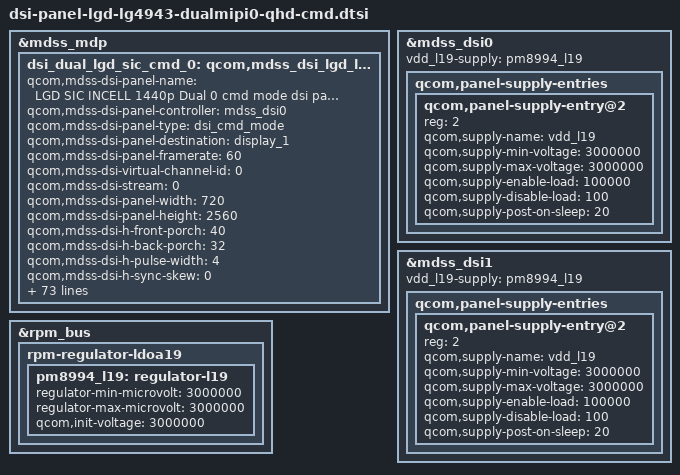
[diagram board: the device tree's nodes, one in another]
/* Copyright (c) 2014, Code Aurora Forum. All rights reserved.
 *
 * This program is free software; you can redistribute it and/or modify
 * it under the terms of the GNU General Public License version 2 and
 * only version 2 as published by the Free Software Foundation.
 *
 * This program is distributed in the hope that it will be useful,
 * but WITHOUT ANY WARRANTY; without even the implied warranty of
 * MERCHANTABILITY or FITNESS FOR A PARTICULAR PURPOSE.  See the
 * GNU General Public License for more details.
 */

&mdss_mdp {
	dsi_dual_lgd_sic_cmd_0: qcom,mdss_dsi_lgd_lg4943_1440p_mipi0_cmd {
		qcom,mdss-dsi-panel-name = "LGD SIC INCELL 1440p Dual 0 cmd mode dsi panel";
		qcom,mdss-dsi-panel-controller = <&mdss_dsi0>;
		qcom,mdss-dsi-panel-type = "dsi_cmd_mode";
		qcom,mdss-dsi-panel-destination = "display_1";
		qcom,mdss-dsi-panel-framerate = <60>;
		qcom,mdss-dsi-virtual-channel-id = <0>;
		qcom,mdss-dsi-stream = <0>;
		qcom,mdss-dsi-panel-width = <720>;
		qcom,mdss-dsi-panel-height = <2560>;
		qcom,mdss-dsi-h-front-porch = <40>;
		qcom,mdss-dsi-h-back-porch = <32>;
		qcom,mdss-dsi-h-pulse-width = <4>;
		qcom,mdss-dsi-h-sync-skew = <0>;
		qcom,mdss-dsi-v-back-porch = <50>;
		qcom,mdss-dsi-v-front-porch = <704>;
		qcom,mdss-dsi-v-pulse-width = <1>;
		qcom,mdss-dsi-h-left-border = <0>;
		qcom,mdss-dsi-h-right-border = <0>;
		qcom,mdss-dsi-v-top-border = <0>;
		qcom,mdss-dsi-v-bottom-border = <0>;
		qcom,mdss-dsi-bpp = <24>;
		qcom,mdss-dsi-color-order = "rgb_swap_rgb";
		qcom,mdss-dsi-underflow-color = <0xff>;
		qcom,mdss-dsi-border-color = <0>;
		qcom,mdss-dsi-h-sync-pulse = <0>;
		qcom,mdss-dsi-traffic-mode = "burst_mode";
		qcom,mdss-dsi-lane-map = "lane_map_0123";
		qcom,mdss-dsi-lane-hs = <1>;
		qcom,mdss-dsi-bllp-eof-power-mode;
		qcom,mdss-dsi-bllp-power-mode;
		qcom,cmd-sync-wait-broadcast;

		qcom,mdss-dsi-lane-0-state;
		qcom,mdss-dsi-lane-1-state;
		qcom,mdss-dsi-lane-2-state;
		qcom,mdss-dsi-lane-3-state;
		qcom,mdss-dsi-hor-line-idle = <0 40 256>,
						<40 120 128>,
						<120 240 64>;
		qcom,mdss-dsi-panel-timings = [F7 3A 28 00 6E 62
						3E 3E 31 03 04 00];//Increase T_HS_prepre 20ns
		qcom,mdss-dsi-reset-sequence = <1 10>, <0 10>, <1 10>;
		qcom,mdss-dsi-t-clk-post = <0x02>;
		lge,mdss-dsi-t-clk-post_for_jdi_ab = <0x32>;
		qcom,mdss-dsi-t-clk-pre = <0x2D>;
		qcom,mdss-dsi-bl-max-level = <4095>;
		qcom,mdss-dsi-dma-trigger = "trigger_sw";
		qcom,mdss-dsi-mdp-trigger = "none";
		qcom,mdss-dsi-te-pin-select = <1>;
		qcom,mdss-dsi-wr-mem-start = <0x2c>;
		qcom,mdss-dsi-wr-mem-continue = <0x3c>;
		qcom,mdss-dsi-te-dcs-command = <1>;
		qcom,mdss-dsi-te-check-enable;
		qcom,mdss-dsi-te-using-te-pin;
		qcom,suspend-ulps-enabled;
		qcom,mdss-dsi-tx-eot-append;
		/* Partial update */
		//qcom,partial-update-enabled;
		qcom,partial-update-roi-merge;
		qcom,panel-roi-alignment = <8 8 4 4 32 32>;
		lge,partial-update-max-left = <1439>;
		lge,partial-update-min-right = <0>;
		qcom,mdss-dsi-on-command = [
			/* Manufacturer Command Protection */
			15 01 00 00 00 00 02 B0 AC
			/* MIPI DPI Configuration */
			39 01 00 00 00 00 06 B1 07 00 80 00 00
			/* Display Control 1 */
			39 01 00 00 00 00 08 B3 0A 14 28 C8 12 94 02
			/* Display Control 2 */
			39 01 00 00 00 00 0B B4 97 B4 0A 0A 0A 0A 14 14 14 14
			/* Display Control 3 */
			39 01 00 00 00 00 0F B5 28 10 20 C8 22 09 09 09 09 D0 50 50 50 50
			/* Display Control 4 */
			39 01 00 00 00 00 05 B6 10 10 A0 00
			/* Display Mode Setting */
			39 01 00 00 00 00 03 B7 4C 00
			/* Panel Setting */
			39 01 00 00 00 00 04 B8 70 91 3F
			/* Internal Oscillator Setting */
			39 01 00 00 00 00 04 C0 10 10 19
			/* Power Control 1 */
			39 01 00 00 00 00 06 C1 01 87 F0 C2 CF
			/* Power Control 2 */
			39 01 00 00 00 00 02 C2 CC
			/* Power Control 3 */
			39 01 00 00 00 00 06 C3 30 74 22 26 21
			/* Power Control 5 */
			39 01 00 00 00 00 07 C5 22 20 A2 52 07 07
			/* Positive Gamma Curve For Red */
			39 01 00 00 00 00 0E D0 8B 10 25 36 44 4C 3F 36 27 19 06 01 03
			/* Negative Gamma Curve For Red */
			39 01 00 00 00 00 0E D1 0B 10 25 36 44 4C 3F 36 27 19 06 01 03
			/* Positive Gamma Curve For Green */
			39 01 00 00 00 00 0E D2 8B 10 25 36 44 4C 3F 36 27 19 06 01 03
			/* Negative Gamma Curve For Green */
			39 01 00 00 00 00 0E D3 0B 10 25 36 44 4C 3F 36 27 19 06 01 03
			/* Positive Gamma Curve For Blue */
			39 01 00 00 00 00 0E D4 8B 10 25 36 44 4C 3F 36 27 19 06 01 03
			/* Negative Gamma Curve For Blue */
			39 01 00 00 00 00 0E D5 0B 10 25 36 44 4C 3F 36 27 19 06 01 03
			/* Left Side GIP Pad Setting */
			39 01 00 00 00 00 12 D6 00 60 00 6B 00 69 00 67 00 65 6C 6D 6E 00 00 00 71
			/* Right Side GIP Pad Setting */
			39 01 00 00 00 00 12 D7 71 00 00 00 6e 6d 6c 64 00 66 00 68 00 6a 00 61 00
			/* Left Side MUX Pad Setting */
			39 01 00 00 00 00 07 D8 78 77 76 75 74 73
			/* Right Side MUX Pad Setting */
			39 01 00 00 00 00 07 D9 73 74 75 76 77 78
			/* LFD Control */
			39 01 00 00 00 00 06 CA BD BD C6 C4 00
			/* Touch Control */
			39 01 00 00 00 00 0D CD D0 07 6E 81 9F 01 02 02 53 F8 05 04
			/* Tearing Effect Line On */
			15 01 00 00 00 00 02 35 00
			/* Write Control Display */
			15 01 00 00 00 00 02 53 24
			/* Write Display Brightness */
			15 01 00 00 00 00 02 51 FF
			/* IE CONTROL */
			15 01 00 00 00 00 02 FA FF
			/* 80 ie on, 01 cabc on, 08 for digital gamma */
			15 01 00 00 00 00 02 55 89
			/* OTP control */
			39 01 00 00 00 00 04 E8 00 00 00
			/* Memory write timing */
			39 01 00 00 00 00 07 E6 21 22 22 22 00 00
			/* Abrrupt Power Off Control */
			15 01 00 00 00 00 02 C9 9F

			/* IE starts */
			/* engine enable 1 */
			39 01 00 00 00 00 02 F0 40   /* 40 all color up, 5~70 selective */
			/* engine enable 2 */
			39 01 00 00 00 00 0F F1 0F 1f 1F 00 00 00 00 00 00 00 00 00 FF 00
			/* engine enable 3 */
			39 01 00 00 00 00 05 F2 01 00 FF 00
			/* engine enable 4 */
			39 01 00 00 00 00 18
			F3 00 43 83 C0 FF
			25 00 50 80 C0 FF // only for SRE
			00 00 40 80 C0 FF
			00 00 40 80 C0 FF

			/* for Wxy shift */
			39 01 00 00 00 00 11
			F7 40 40 40 40 40 40 40 40
			00 00 00 00 00 00 00 00

			39 01 00 00 00 00 11
			F8 3E 3E 3E 3E 3E 3E 3E 3E
			00 00 00 00 00 00 00 00

			39 01 00 00 00 00 11
			F9 3E 3E 3E 3E 3E 3E 3E 3E
			00 00 00 00 00 00 00 00

			/* CABC */
			39 01 00 00 00 00 07
			B9 13 00 00 78 7F 80
			/* IE ends */

			/* SRE setting START*/
			39 01 00 00 00 00 19
			FC 0F 60 75 87 A8
			C0 E4 F0 00 40 70
			90 A0 B0 C0 F0 00
			20 40 60 80 A0 C0
			E0
			/* SRE setting END*/

			/* Sleep Out  */
			05 01 00 00 55 00 01 11 /* 85ms */
			/* OSC setting */
			39 01 00 00 00 00 04 C0 10 90 16
			/* Display On */
			05 01 00 00 00 00 01 29
			];
		lge,mdss-dsi-clk_on-command = [
			/* Manufacturer Command Protection */
			15 01 00 00 00 00 02 B0 AC
			/* MIPI DPI Configuration */
			39 01 00 00 00 00 06 B1 07 00 80 00 00
			/* Display Control 1 */
			39 01 00 00 00 00 08 B3 0A 14 28 C8 12 94 02
			/* Display Control 2 */
			39 01 00 00 00 00 0B B4 97 B4 0A 0A 0A 0A 14 14 14 14
			/* Display Control 3 */
			39 01 00 00 00 00 0F B5 28 10 20 C8 22 09 09 09 09 D0 50 50 50 50
			/* Display Control 4 */
			39 01 00 00 00 00 05 B6 10 10 A0 00
			/* Display Mode Setting */
			39 01 00 00 00 00 03 B7 4C 00
			/* Panel Setting */
			39 01 00 00 00 00 04 B8 70 91 3F
			/* Internal Oscillator Setting */
			39 01 00 00 00 00 04 C0 10 10 19
			/* Power Control 1 */
			39 01 00 00 00 00 06 C1 01 87 F0 C2 CF
			/* Power Control 2 */
			39 01 00 00 00 00 02 C2 CC
			/* Power Control 3 */
			39 01 00 00 00 00 06 C3 30 74 22 26 21
			/* Power Control 5 */
			39 01 00 00 00 00 07 C5 22 20 A2 52 07 07
			/* Positive Gamma Curve For Red */
			39 01 00 00 00 00 0E D0 8B 10 25 36 44 4C 3F 36 27 19 06 01 03
			/* Negative Gamma Curve For Red */
			39 01 00 00 00 00 0E D1 0B 10 25 36 44 4C 3F 36 27 19 06 01 03
			/* Positive Gamma Curve For Green */
			39 01 00 00 00 00 0E D2 8B 10 25 36 44 4C 3F 36 27 19 06 01 03
			/* Negative Gamma Curve For Green */
			39 01 00 00 00 00 0E D3 0B 10 25 36 44 4C 3F 36 27 19 06 01 03
			/* Positive Gamma Curve For Blue */
			39 01 00 00 00 00 0E D4 8B 10 25 36 44 4C 3F 36 27 19 06 01 03
			/* Negative Gamma Curve For Blue */
			39 01 00 00 00 00 0E D5 0B 10 25 36 44 4C 3F 36 27 19 06 01 03
			/* Left Side GIP Pad Setting */
			39 01 00 00 00 00 12 D6 00 60 00 6B 00 69 00 67 00 65 6C 6D 6E 00 00 00 71
			/* Right Side GIP Pad Setting */
			39 01 00 00 00 00 12 D7 71 00 00 00 6e 6d 6c 64 00 66 00 68 00 6a 00 61 00
			/* Left Side MUX Pad Setting */
			39 01 00 00 00 00 07 D8 78 77 76 75 74 73
			/* Right Side MUX Pad Setting */
			39 01 00 00 00 00 07 D9 73 74 75 76 77 78
			/* LFD Control */
			39 01 00 00 00 00 06 CA BD BD C6 C4 00
			/* Touch Control */
			39 01 00 00 00 00 0D CD D0 07 6E 81 9F 01 02 02 53 F8 05 04
			/* Tearing Effect Line On */
			15 01 00 00 00 00 02 35 00
			/* Write Control Display */
			15 01 00 00 00 00 02 53 24
			/* Write Display Brightness */
			15 01 00 00 00 00 02 51 FF
			/* OTP control */
			39 01 00 00 00 00 04 E8 00 00 00
			/* Memory write timing */
			39 01 00 00 00 00 07 E6 21 22 22 22 00 00
			/* Abrrupt Power Off Control */
			15 01 00 00 64 00 02 C9 9F
			/* OSC setting */
			39 01 00 00 00 00 04 C0 10 90 16
			];
		lge,mdss-dsi-clk_off-command = [
			/* Manufacturer Command Protection */
			15 01 00 00 00 00 02 B0 AC
			/* MIPI DPI Configuration */
			39 01 00 00 00 00 06 B1 07 00 80 00 00
			/* Display Control 1 */
			39 01 00 00 00 00 08 B3 0A 14 28 C8 12 94 02
			/* Display Control 2 */
			39 01 00 00 00 00 0B B4 97 B4 0A 0A 0A 0A 14 14 14 14
			/* Display Control 3 */
			39 01 00 00 00 00 0F B5 28 10 20 C8 22 09 09 09 09 D0 50 50 50 50
			/* Display Control 4 */
			39 01 00 00 00 00 05 B6 10 10 A0 00
			/* Display Mode Setting */
			39 01 00 00 00 00 03 B7 4C 00
			/* Panel Setting */
			39 01 00 00 00 00 04 B8 70 91 3F
			/* Internal Oscillator Setting */
			39 01 00 00 00 00 04 C0 10 10 19
			/* Power Control 1 */
			39 01 00 00 00 00 06 C1 01 87 F0 C2 CF
			/* Power Control 2 */
			39 01 00 00 00 00 02 C2 CC
			/* Power Control 3 */
			39 01 00 00 00 00 06 C3 30 74 22 26 21
			/* Power Control 5 */
			39 01 00 00 00 00 07 C5 22 20 A2 52 07 07
			/* Positive Gamma Curve For Red */
			39 01 00 00 00 00 0E D0 8B 10 25 36 44 4C 3F 36 27 19 06 01 03
			/* Negative Gamma Curve For Red */
			39 01 00 00 00 00 0E D1 0B 10 25 36 44 4C 3F 36 27 19 06 01 03
			/* Positive Gamma Curve For Green */
			39 01 00 00 00 00 0E D2 8B 10 25 36 44 4C 3F 36 27 19 06 01 03
			/* Negative Gamma Curve For Green */
			39 01 00 00 00 00 0E D3 0B 10 25 36 44 4C 3F 36 27 19 06 01 03
			/* Positive Gamma Curve For Blue */
			39 01 00 00 00 00 0E D4 8B 10 25 36 44 4C 3F 36 27 19 06 01 03
			/* Negative Gamma Curve For Blue */
			39 01 00 00 00 00 0E D5 0B 10 25 36 44 4C 3F 36 27 19 06 01 03
			/* Left Side GIP Pad Setting */
			39 01 00 00 00 00 12 D6 00 60 00 6B 00 69 00 67 00 65 6C 6D 6E 00 00 00 71
			/* Right Side GIP Pad Setting */
			39 01 00 00 00 00 12 D7 71 00 00 00 6e 6d 6c 64 00 66 00 68 00 6a 00 61 00
			/* Left Side MUX Pad Setting */
			39 01 00 00 00 00 07 D8 78 77 76 75 74 73
			/* Right Side MUX Pad Setting */
			39 01 00 00 00 00 07 D9 73 74 75 76 77 78
			/* LFD Control */
			39 01 00 00 00 00 06 CA BD BD C6 C4 00
			/* Touch Control */
			39 01 00 00 00 00 0D CD D0 07 6E 81 9F 01 02 02 53 F8 05 04
			/* Tearing Effect Line On */
			15 01 00 00 00 00 02 35 00
			/* Write Control Display */
			15 01 00 00 00 00 02 53 24
			/* Write Display Brightness */
			15 01 00 00 00 00 02 51 FF
			/* OTP control */
			39 01 00 00 00 00 04 E8 00 00 00
			/* Memory write timing */
			39 01 00 00 00 00 07 E6 21 22 22 22 00 00
			/* Abrrupt Power Off Control */
			15 01 00 00 00 00 02 C9 9F
			/* touch sensing clk down */
			39 01 00 00 00 00 06 EB 38 00 00 E0 0E
			];
		qcom,mdss-dsi-on-command-state = "dsi_lp_mode";
		lge,mdss-dsi-clk_on-command-state = "dsi_lp_mode";
		lge,mdss-dsi-clk_off-command-state = "dsi_lp_mode";
		qcom,mdss-dsi-off-command = [
			05 01 00 00 0A 00 02 28 00
			05 01 00 00 55 00 02 10 00  /* 85ms */
			/* Sleep In 1*/
			39 01 00 00 00 00 07 D8 58 57 56 55 54 53
			/* Sleep In 2*/
			39 01 00 00 00 00 07 D9 53 54 55 56 57 58
			/* Sleep In 3*/
			39 01 00 00 00 00 06 EB 38 00 00 10 0E
			];
		qcom,mdss-dsi-off-command-state = "dsi_hs_mode";
		qcom,cont-splash-enabled;
		/* SRE cmds set START*/
		qcom,sre-control-dsi-state = "dsi_lp_mode";
		lge,sre-cmds-off = [
			15 01 00 00 00 00 02 F0 40
			15 01 00 00 00 00 02 55 89
		];
		lge,sre-cmds-on = [
			15 01 00 00 00 00 02 F0 50
			15 01 00 00 00 00 02 55 C8
		];
		/* SRE cmds set END*/
		qcom,blmap-size = <256>;
		qcom,blmap = <
                          0
                          1 5 5 10 10 15 20 20 25 25
                          30 46 62 78 94 110 126 142 158 174
                          190 206 222 238 254 270 286 302 318 334
                          350 366 382 398 414 430 446 462 478 494
                          510 526 542 558 574 590 606 622 638 654
                          670 686 702 718 734 750 766 782 798 814
                          830 846 862 878 894 910 926 942 958 974
                          990 1006 1022 1038 1054 1070 1086 1102 1118 1134
                          1150 1166 1182 1198 1214 1230 1246 1262 1278 1294
                          1310 1326 1342 1358 1374 1390 1406 1422 1438 1454
                          1470 1486 1502 1518 1534 1550 1566 1582 1598 1614
                          1630 1646 1662 1678 1694 1710 1726 1742 1758 1774
                          1790 1806 1822 1838 1854 1870 1886 1902 1918 1934
                          1950 1966 1982 1998 2014 2030 2046 2062 2078 2094
                          2110 2126 2142 2158 2174 2190 2206 2222 2238 2254
                          2270 2286 2302 2318 2334 2350 2366 2382 2398 2414
                          2430 2446 2462 2478 2494 2510 2526 2542 2558 2574
                          2590 2606 2622 2638 2654 2670 2686 2702 2718 2734
                          2750 2766 2782 2798 2814 2830 2846 2862 2878 2894
                          2910 2926 2942 2958 2974 2990 3006 3022 3038 3054
                          3070 3086 3102 3118 3134 3150 3166 3182 3198 3214
                          3230 3246 3262 3278 3294 3310 3326 3342 3358 3374
                          3390 3406 3422 3438 3454 3470 3486 3502 3518 3534
                          3550 3566 3582 3598 3614 3630 3646 3662 3678 3694
                          3710 3726 3742 3758 3774 3790 3806 3822 3838 3854
                          3870 3886 3902 3918 4000
		>;
		qcom,blmap_store_mode = <
			  0
			  1 5 10 10 15 15 20 20 29 29
			  29 29 29 30 30 30 31 31 31 32
			  32 32 33 34 36 38 40 42 44 45
			  47 49 51 53 55 57 59 61 63 65
			  67 70 72 74 76 78 80 82 85 91
			  97 103 110 116 122 129 135 141 148 153
			  159 165 170 176 182 188 193 199 205 210
			  216 222 228 235 243 251 258 266 274 281
			  289 297 304 312 320 327 335 343 351 359
			  367 374 382 390 398 406 414 422 434 446
			  459 471 483 496 508 520 533 545 558 569
			  580 591 602 614 625 636 647 659 670 681
			  692 704 718 733 747 762 776 791 805 820
			  834 849 863 878 895 912 930 947 965 982
			  1000 1017 1035 1052 1070 1088 1106 1125 1143 1162
			  1180 1199 1217 1236 1254 1273 1291 1310 1330 1351
			  1372 1393 1414 1435 1455 1476 1497 1518 1539 1560
			  1582 1604 1626 1648 1670 1692 1715 1737 1759 1781
			  1803 1825 1848 1872 1896 1921 1945 1969 1994 2018
			  2042 2067 2091 2115 2140 2166 2192 2218 2244 2270
			  2296 2323 2349 2375 2401 2427 2453 2480 2512 2545
			  2578 2610 2643 2676 2709 2741 2774 2807 2840 2870
			  2901 2932 2963 2993 3024 3055 3086 3116 3147 3178
			  3209 3240 3275 3311 3347 3383 3419 3455 3490 3526
			  3562 3598 3634 3670 3708 3747 3785 3824 3863 3901
			  3940 3979 4017 4056 4095
		>;
		qcom,mdss-pan-physical-width-dimension = <68>;
		qcom,mdss-pan-physical-height-dimension = <121>;

		lge,panel_power_sequence = <
			0    /*pre_msm_dss_enable_vreg*/
			0    /*post_msm_dss_enable_vreg*/
			0    /*pre_mdss_dsi_panel_reset*/
			0    /*post_mdss_dsi_panel_reset*/
			1    /*pre_mdss_dsi_panel_power_ctrl*/
			1    /*post_mdss_dsi_panel_power_ctrl*/
			0    /*post_mdss_dsi_blank*/
			1    /*post_mdss_dsi_panel_on*/
			0    /*post_mdss_dsi_panel_off*/
			1    /*lge_mdss_dsi_event_handler*/
			1    /*lge_msm_dss_enable_vreg*/
			1    /*lge_mdss_dsi_request_gpios*/
			1    /*lge_mdss_dsi_panel_reset*/
			0    /*lge_mdss_dsi_lane_config*/
			1    /*lge_mdss_dsi_ctrl_probe*/
			1    /*lge_dsi_panel_device_register*/
			1    /*lge_mdss_panel_parse_dt*/
			0    /*lge_panel_device_create*/
			1    /*lge_mdss_dsi_cmdlist_commit*/
			1    /*lge_mdss_dsi_panel_init*/
			1    /*lge_dump_mdss_reg*/
			1    /*lge_mdss_xlog_tout_handler_default*/
			0    /*lge_mdss_create_xlog_debug*/
			1    /*lge_mdss_dsi_panel_bl_ctrl*/
			>;
	};
};

&mdss_dsi0 {
	vdd_l19-supply = <&pm8994_l19>;

	qcom,panel-supply-entries {
			qcom,panel-supply-entry@2 {
				reg = <2>;
				qcom,supply-name = "vdd_l19";
				qcom,supply-min-voltage = <3000000>;
				qcom,supply-max-voltage = <3000000>;
				qcom,supply-enable-load = <100000>;
				qcom,supply-disable-load = <100>;
				qcom,supply-post-on-sleep = <20>;
			};
		};
};

&mdss_dsi1 {
	vdd_l19-supply = <&pm8994_l19>;

	qcom,panel-supply-entries {
			qcom,panel-supply-entry@2 {
				reg = <2>;
				qcom,supply-name = "vdd_l19";
				qcom,supply-min-voltage = <3000000>;
				qcom,supply-max-voltage = <3000000>;
				qcom,supply-enable-load = <100000>;
				qcom,supply-disable-load = <100>;
				qcom,supply-post-on-sleep = <20>;
			};
		};
};

&rpm_bus {
	rpm-regulator-ldoa19 {
		status = "okay";
		pm8994_l19: regulator-l19 {
			regulator-min-microvolt = <3000000>;
			regulator-max-microvolt = <3000000>;
			qcom,init-voltage = <3000000>;
			status = "okay";
		};
	};
};

